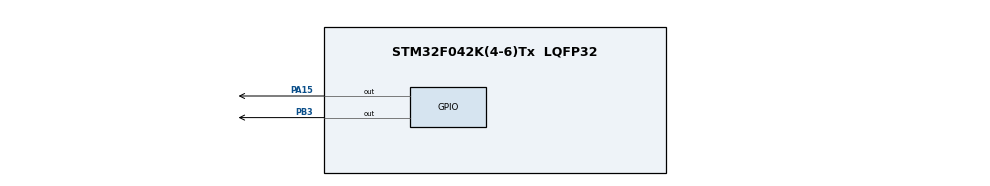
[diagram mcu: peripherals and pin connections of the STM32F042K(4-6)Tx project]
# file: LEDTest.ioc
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Mcu.Family=STM32F0
Mcu.Name=STM32F042K(4-6)Tx
Mcu.Package=LQFP32
Mcu.UserConstants=LED_FLASH_TOGGLE_PERIOD_MS,500
NVIC.TIM14_IRQn=true\:0\:0\:false\:false\:true\:true\:true
PA15.Signal=GPIO_Output
PB3.Signal=GPIO_Output
ProjectManager.HeapSize=0x200
ProjectManager.StackSize=0x400
ProjectManager.TargetToolchain=STM32CubeIDE
TIM14.Period=LED_FLASH_TOGGLE_PERIOD_MS - 1
TIM14.Prescaler=8000 - 1
VP_TIM14_VS_ClockSourceINT.Mode=Enable_Timer
board=custom

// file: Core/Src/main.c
/* USER CODE BEGIN Header */
/**
  ******************************************************************************
  * @file           : main.c
  * @brief          : Main program body
  ******************************************************************************
  * @attention
  *
  * <h2><center>&copy; Copyright (c) 2021 STMicroelectronics.
  * All rights reserved.</center></h2>
  *
  * This software component is licensed by ST under BSD 3-Clause license,
  * the "License"; You may not use this file except in compliance with the
  * License. You may obtain a copy of the License at:
  *                        opensource.org/licenses/BSD-3-Clause
  *
  ******************************************************************************
  */
/* USER CODE END Header */
#include "main.h"

/* USER CODE BEGIN Includes */
#pragma GCC diagnostic warning "-Wunused-macros"
#pragma GCC diagnostic warning "-Wunused-parameter"
#pragma GCC diagnostic warning "-Wsign-compare"
#pragma GCC diagnostic warning "-Wconversion"
#pragma GCC diagnostic warning "-Wredundant-decls"
#pragma GCC diagnostic warning "-Wswitch-default"
#pragma GCC diagnostic warning "-Wswitch-enum"

/* USER CODE END Includes */

/* USER CODE BEGIN PD */

#define LED_PIN_PORT 'A'
#define LED_PIN_NUMBER 15
#define LED_FLASH_ENABLED 1
// LED_FLASH_TOGGLE_PERIOD_MS is in main.h. To change it, edit the .ioc file.

/* USER CODE END PD */

TIM_HandleTypeDef htim14;

/* USER CODE BEGIN PV */

#if (LED_PIN_PORT == 'A' || LED_PIN_PORT == 'a')
  GPIO_TypeDef *ledPinPort = GPIOA;
#elif (LED_PIN_PORT == 'B' || LED_PIN_PORT == 'b')
  GPIO_TypeDef *ledPinPort = GPIOB;
#elif (LED_PIN_PORT == 'C' || LED_PIN_PORT == 'c')
  GPIO_TypeDef *ledPinPort = GPIOC;
#else
  #error "Need a valid LED_PIN_PORT"
#endif
uint16_t ledPinNumber = (uint16_t)(1 << LED_PIN_NUMBER);

/* USER CODE END PV */

void SystemClock_Config(void);
static void MX_GPIO_Init(void);
static void MX_TIM14_Init(void);
/* USER CODE BEGIN PFP */

void TIM14_TimerElapsedCallback(TIM_HandleTypeDef *_htim);

/* USER CODE END PFP */

int main(void)
{

  /* MCU Configuration--------------------------------------------------------*/

  /* Reset of all peripherals, Initializes the Flash interface and the Systick. */
  HAL_Init();

  /* Configure the system clock */
  SystemClock_Config();

  /* Initialize all configured peripherals */
  MX_GPIO_Init();
  MX_TIM14_Init();
  /* USER CODE BEGIN 2 */

  //  Used to the LED change state during debugging mode
  HAL_GPIO_WritePin(ledPinPort,  ledPinNumber, GPIO_PIN_RESET);

  HAL_GPIO_WritePin(ledPinPort,  ledPinNumber, GPIO_PIN_SET);

  HAL_GPIO_WritePin(ledPinPort,  ledPinNumber, GPIO_PIN_RESET);

  HAL_GPIO_WritePin(ledPinPort,  ledPinNumber, GPIO_PIN_SET);

  HAL_GPIO_WritePin(ledPinPort,  ledPinNumber, GPIO_PIN_RESET);

#if (LED_FLASH_ENABLED != 0)
  HAL_TIM_Base_Start_IT(&htim14);
#endif

  /* USER CODE END 2 */

  /* Infinite loop */
  while (1)
  {

  }
}

void SystemClock_Config(void)
{
  RCC_OscInitTypeDef RCC_OscInitStruct = {0};
  RCC_ClkInitTypeDef RCC_ClkInitStruct = {0};

  /** Initializes the RCC Oscillators according to the specified parameters
  * in the RCC_OscInitTypeDef structure.
  */
  RCC_OscInitStruct.OscillatorType = RCC_OSCILLATORTYPE_HSI;
  RCC_OscInitStruct.HSIState = RCC_HSI_ON;
  RCC_OscInitStruct.HSICalibrationValue = RCC_HSICALIBRATION_DEFAULT;
  RCC_OscInitStruct.PLL.PLLState = RCC_PLL_NONE;
  if (HAL_RCC_OscConfig(&RCC_OscInitStruct) != HAL_OK)
  {
    Error_Handler();
  }
  /** Initializes the CPU, AHB and APB buses clocks
  */
  RCC_ClkInitStruct.ClockType = RCC_CLOCKTYPE_HCLK|RCC_CLOCKTYPE_SYSCLK
                              |RCC_CLOCKTYPE_PCLK1;
  RCC_ClkInitStruct.SYSCLKSource = RCC_SYSCLKSOURCE_HSI;
  RCC_ClkInitStruct.AHBCLKDivider = RCC_SYSCLK_DIV1;
  RCC_ClkInitStruct.APB1CLKDivider = RCC_HCLK_DIV1;

  if (HAL_RCC_ClockConfig(&RCC_ClkInitStruct, FLASH_LATENCY_0) != HAL_OK)
  {
    Error_Handler();
  }
}

static void MX_TIM14_Init(void)
{

  htim14.Instance = TIM14;
  htim14.Init.Prescaler = 8000 - 1;
  htim14.Init.CounterMode = TIM_COUNTERMODE_UP;
  htim14.Init.Period = LED_FLASH_TOGGLE_PERIOD_MS - 1;
  htim14.Init.ClockDivision = TIM_CLOCKDIVISION_DIV1;
  htim14.Init.AutoReloadPreload = TIM_AUTORELOAD_PRELOAD_DISABLE;
  if (HAL_TIM_Base_Init(&htim14) != HAL_OK)
  {
    Error_Handler();
  }
  /* USER CODE BEGIN TIM14_Init 2 */
  //  Clear Status Register from any pending Update Events due to initialization
  htim14.Instance->SR = 0;

  //  Configure LED Flash Frequency
  htim14.Instance->ARR = htim14.Init.Period;

  //  Set Timer Interrupt Update Callback Function
  HAL_TIM_RegisterCallback(&htim14, HAL_TIM_PERIOD_ELAPSED_CB_ID, TIM14_TimerElapsedCallback);

  /* USER CODE END TIM14_Init 2 */

}

static void MX_GPIO_Init(void)
{
  GPIO_InitTypeDef GPIO_InitStruct = {0};

  /* GPIO Ports Clock Enable */
#if (LED_PIN_PORT == 'A' || LED_PIN_PORT == 'a')
  __HAL_RCC_GPIOA_CLK_ENABLE();
#elif (LED_PIN_PORT == 'B' || LED_PIN_PORT == 'b')
  __HAL_RCC_GPIOB_CLK_ENABLE();
#elif (LED_PIN_PORT == 'C' || LED_PIN_PORT == 'c')
  __HAL_RCC_GPIOC_CLK_ENABLE();
#else
  #error "Need a valid LED_PIN_PORT"
#endif

  /* Configure GPIO pin Output Level */
  HAL_GPIO_WritePin(ledPinPort, ledPinNumber, GPIO_PIN_RESET);

  /* Configure GPIO pin : PA15 */
  GPIO_InitStruct.Pin = ledPinNumber;
  GPIO_InitStruct.Mode = GPIO_MODE_OUTPUT_PP;
  GPIO_InitStruct.Pull = GPIO_NOPULL;
  GPIO_InitStruct.Speed = GPIO_SPEED_FREQ_LOW;
  HAL_GPIO_Init(ledPinPort, &GPIO_InitStruct);
}

/* USER CODE BEGIN 4 */

void TIM14_TimerElapsedCallback(TIM_HandleTypeDef *_htim)
{
	HAL_GPIO_TogglePin(ledPinPort, ledPinNumber);
}

/* USER CODE END 4 */

void Error_Handler(void)
{
}

/************************ (C) COPYRIGHT STMicroelectronics *****END OF FILE****/
